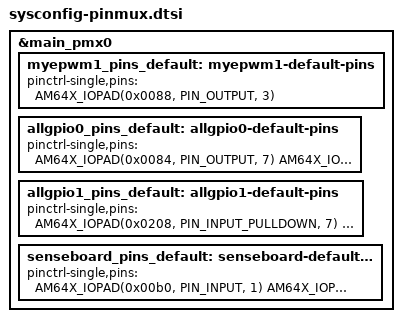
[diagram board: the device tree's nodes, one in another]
/* This file was auto-generated by TI PinMux on 1/14/2026 at 9:40:01 PM. */
/* This file should only be used as a reference. Some pins/peripherals, */
/* depending on your use case, may need additional configuration. */

&main_pmx0 {
	myepwm1_pins_default: myepwm1-default-pins {
		pinctrl-single,pins = <
			AM64X_IOPAD(0x0088, PIN_OUTPUT, 3) /* (R18) GPMC0_OEn_REn.EHRPWM4_A */
		>;
	};
	allgpio0_pins_default: allgpio0-default-pins {
		pinctrl-single,pins = <
			AM64X_IOPAD(0x0084, PIN_OUTPUT, 7) /* (P16) GPMC0_ADVn_ALE.GPIO0_32 */
			AM64X_IOPAD(0x008c, PIN_INPUT_PULLDOWN, 7) /* (T21) GPMC0_WEn.GPIO0_34 */
			AM64X_IOPAD(0x0090, PIN_OUTPUT, 7) /* (P17) GPMC0_BE0n_CLE.GPIO0_35 */
			AM64X_IOPAD(0x0094, PIN_INPUT_PULLDOWN, 7) /* (T19) GPMC0_BE1n.GPIO0_36 */
			AM64X_IOPAD(0x0098, PIN_INPUT_PULLDOWN, 7) /* (W19) GPMC0_WAIT0.GPIO0_37 */
			AM64X_IOPAD(0x009c, PIN_OUTPUT, 7) /* (Y18) GPMC0_WAIT1.GPIO0_38 */
			AM64X_IOPAD(0x00a0, PIN_INPUT_PULLDOWN, 7) /* (N16) GPMC0_WPn.GPIO0_39 */
			AM64X_IOPAD(0x00a4, PIN_OUTPUT, 7) /* (N17) GPMC0_DIR.GPIO0_40 */
			AM64X_IOPAD(0x00ac, PIN_OUTPUT, 7) /* (R20) GPMC0_CSn1.GPIO0_42 */
		>;
	};
	allgpio1_pins_default: allgpio1-default-pins {
		pinctrl-single,pins = <
			AM64X_IOPAD(0x0208, PIN_INPUT_PULLDOWN, 7) /* (D12) SPI0_CS0.GPIO1_42 */
			AM64X_IOPAD(0x020c, PIN_INPUT_PULLDOWN, 7) /* (C13) SPI0_CS1.GPIO1_43 */
			AM64X_IOPAD(0x0210, PIN_OUTPUT, 7) /* (D13) SPI0_CLK.GPIO1_44 */
			AM64X_IOPAD(0x0218, PIN_INPUT_PULLDOWN, 7) /* (A14) SPI0_D1.GPIO1_46 */
			AM64X_IOPAD(0x0220, PIN_OUTPUT, 7) /* (D14) SPI1_CS1.GPIO1_48 */
			AM64X_IOPAD(0x022c, PIN_INPUT_PULLDOWN, 7) /* (A15) SPI1_D1.GPIO1_51 */
			AM64X_IOPAD(0x0258, PIN_OUTPUT, 7) /* (C17) MCAN1_TX.GPIO1_62 */
			AM64X_IOPAD(0x025c, PIN_OUTPUT, 7) /* (D17) MCAN1_RX.GPIO1_63 */
			AM64X_IOPAD(0x0260, PIN_OUTPUT, 7) /* (A18) I2C0_SCL.GPIO1_64 */
			AM64X_IOPAD(0x0264, PIN_OUTPUT, 7) /* (B18) I2C0_SDA.GPIO1_65 */
		>;
	};
	senseboard_pins_default: senseboard-default-pins {
		pinctrl-single,pins = <
			AM64X_IOPAD(0x00b0, PIN_INPUT, 1) /* (P19) GPMC0_CSn2.I2C2_SCL */
			AM64X_IOPAD(0x00b4, PIN_INPUT, 1) /* (R21) GPMC0_CSn3.I2C2_SDA */
		>;
	};
};

